# QN908XC register map
Vendor: nxp.com; File version: 1.0
CPU: CM4 r0p1, little endian, no MPU, no FPU, 0x3 interrupt priority bits, 0x0 interrupts
Registers are 32-bit, read-write, reset 0x0 unless marked. A register's access mark holds for its fields unless they carry their own. Offsets are from the block's base; [hi:lo] are bit positions.

## AGC
Base 0x4000C000
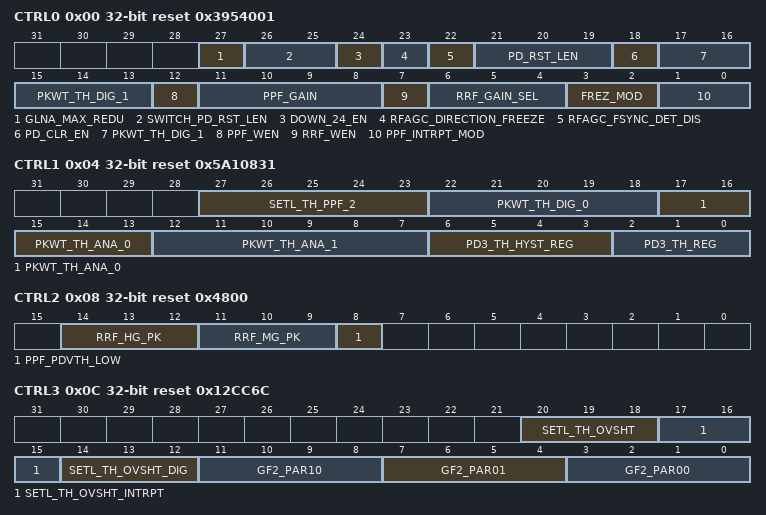
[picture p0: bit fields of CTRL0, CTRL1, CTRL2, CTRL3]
0x00 CTRL0 reset 0x3954001 — AGC control register 0
  [27] GLNA_MAX_REDU — Lna max gain reduce 12dbm0bdisable 1benable
  [26:25] SWITCH_PD_RST_LEN — Pd disable time when direction found rfagc reset00b2us 01b4us 10b8us 11b16us
  [24] DOWN_24_EN — Lna decrease 24dbm0bdisable 1benable
  [23] RFAGC_DIRECTION_FREEZE — Use to disable rfagc gain adjust when switching antenna at direction found mode0b rfagc enable 1brfagc disable
  [22] RFAGC_FSYNC_DET_DIS — Use to control rfagc gain adjust0brfagc stops when sync 1brfagc always on
  [21:19] PD_RST_LEN — Pd disable time when reset0h0us 1h8us 2h16us 7h56us
  [18] PD_CLR_EN — Force clear analog PD
  [17:13] PKWT_TH_DIG_1 — PKWT_TH_DIG + PKWT_TH_DIG_ADD in ccode
  [12] PPF_WEN — Ppf gain write enable
  [11:8] PPF_GAIN — PPF gain controlGain=36-3*PPF_GAIN
  [7] RRF_WEN — Lna gain write enable
  [6:4] RRF_GAIN_SEL — LNA gain controlGAIN=26-12*LNA_GAIN_SEL
  [3:2] FREZ_MOD — Control whether fsm can restore last value when correalation trigh happens
  [1:0] PPF_INTRPT_MOD — Control whether fsm can interrupt
0x04 CTRL1 reset 0x5A10831 — AGC control register 1
  [27:23] SETL_TH_PPF_2 — SETL_TH_PPF_2 + DLY_DIG 1 in ccode
  [22:18] PKWT_TH_DIG_0 — PKWT_TH_DIG in ccode
  [17:13] PKWT_TH_ANA_0 — PKWT_TH_ANA in ccode
  [12:7] PKWT_TH_ANA_1 — PKWT_TH_ANA + PKWT_TH_ANA_ADD
  [6:3] PD3_TH_HYST_REG — Desired upper boundary
  [2:0] PD3_TH_REG — Pd3 threshold
0x08 CTRL2 reset 0x4800 — AGC control register 2
  [14:12] RRF_HG_PK — LNA high gain peak detect threshold selectAMP=(100-8* LNA_HG_PK)mv
  [11:9] RRF_MG_PK — LNA medium gain peak detect threshold selectAMP=(400-25* LNA_MG_PK)mv
  [8] PPF_PDVTH_LOW — PPF peak detect threshold select
0x0C CTRL3 reset 0x12CC6C — AGC control register 3
  [20:18] SETL_TH_OVSHT, [17:15] SETL_TH_OVSHT_INTRPT, [14:12] SETL_TH_OVSHT_DIG, [11:8] GF2_PAR10, [7:4] GF2_PAR01, [3:0] GF2_PAR00
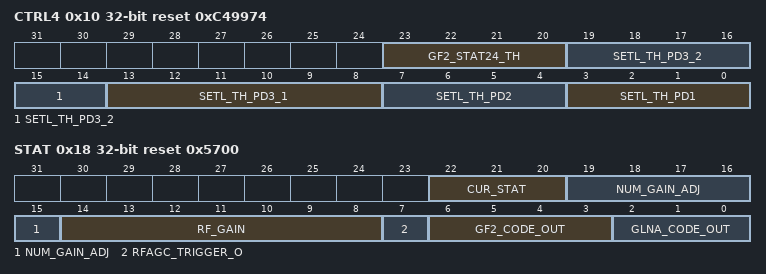
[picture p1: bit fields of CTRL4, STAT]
0x10 CTRL4 reset 0xC49974 — AGC control register 4
  [23:20] GF2_STAT24_TH, [19:14] SETL_TH_PD3_2, [13:8] SETL_TH_PD3_1, [7:4] SETL_TH_PD2, [3:0] SETL_TH_PD1
0x14 CTRL5 — AGC control register 5
  [3:0] TEST_CTRL
0x18 STAT ro reset 0x5700 — AGC status register
  [22:20] CUR_STAT, [19:15] NUM_GAIN_ADJ, [14:8] RF_GAIN, [7] RFAGC_TRIGGER_O, [6:3] GF2_CODE_OUT, [2:0] GLNA_CODE_OUT

## PROP
Base 0x4000D000
0x00 TX_BUF — transmit data buffer input port register
  [7:0] TX_BUF
0x04 RX_BUF ro — received data buffer output register
  [7:0] RX_BUF
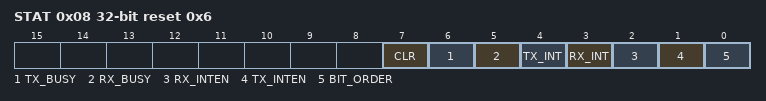
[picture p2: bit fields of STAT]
0x08 STAT reset 0x6 — status register
  [7] CLR — Clear intf control register.
  [6] TX_BUSY ro — TX is busy
  [5] RX_BUSY ro — RX is busy
  [4] TX_INT ro — TX interrupt
  [3] RX_INT ro — RX interrupt
  [2] RX_INTEN — RX interrupt enable
  [1] TX_INTEN — TX interrupt enable
  [0] BIT_ORDER

## FLEXCOMM0 — flexcomm
Base 0x40083000
Same registers: FLEXCOMM1 0x40086000, FLEXCOMM2 0x40087000, FLEXCOMM3 0x4008F000
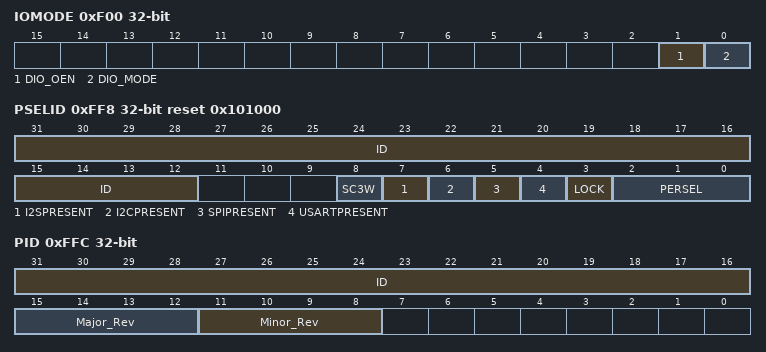
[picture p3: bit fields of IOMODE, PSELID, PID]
0xF00 IOMODE
  [1] DIO_OEN — shared pin direction register
    0=SP_NOEN (shared pin do not output); 1=SP_OEN (shared pin output enable)
  [0] DIO_MODE — IO mode register, SPI share MISO/MOSI at MOSI, USART share TXD/RXD at RXD
    0=NOSHAREPIN (do not share pin); 1=SHAREPIN
0xFF8 PSELID reset 0x101000 — Peripheral Select and Flexcomm ID register.
  [31:12] ID ro — Flexcomm ID.
  [8] SC3W ro — Smart card/SPI 3 wire mode feature indicator. This field is Read-only
    0=NOT_PRESENT (This Flexcomm does not support smart card/SPI 3 wire mdoe feature); 1=PRESENT (This Flexcomm support smart card/SPI 3 wire mode feature)
  [7] I2SPRESENT ro — I 2S present indicator. This field is Read-only.
    0=NOT_PRESENT (This Flexcomm does not include the I2S function.); 1=PRESENT (This Flexcomm includes the I2S function.)
  [6] I2CPRESENT ro — I2C present indicator. This field is Read-only.
    0=NOT_PRESENT (This Flexcomm does not include the I2C function.); 1=PRESENT (This Flexcomm includes the I2C function.)
  [5] SPIPRESENT ro — SPI present indicator. This field is Read-only.
    0=NOT_PRESENT (This Flexcomm does not include the SPI function.); 1=PRESENT (This Flexcomm includes the SPI function.)
  [4] USARTPRESENT ro — USART present indicator. This field is Read-only.
    0=NOT_PRESENT (This Flexcomm does not include the USART function.); 1=PRESENT (This Flexcomm includes the USART function.)
  [3] LOCK — Lock the peripheral select. This field is writable by software.
    0=UNLOCKED (Peripheral select can be changed by software.); 1=LOCKED (Peripheral select is locked and cannot be changed until this Flexcomm or the entire device is reset.)
  [2:0] PERSEL — Peripheral Select. This field is writable by software.
    0=NO_PERIPH_SELECTED (No peripheral selected.); 1=USART (USART function selected.); 2=SPI (SPI function selected.); 3=I2C (I2C function selected.); 4=I2S_TRANSMIT (I2S transmit function selected.); 5=I2S_RECEIVE (I2S receive function selected.)
0xFFC PID ro — Peripheral identification register.
  [31:16] ID — Module identifier for the selected function.
  [15:12] Major_Rev — Major revision of module implementation.
  [11:8] Minor_Rev — Minor revision of module implementation.

## GPIOA — gpio
Base 0x4008C000
Same registers: GPIOB 0x4008D000
0x00 DATA ro — GPIO value register
  [31:0] DATA — data value
0x04 DATAOUT — GPIO output status register
  [31:0] DATAOUT — Data output register value
0x10 OUTENSET — GPIO output enable set register
  [31:0] OUTENSET — output enable clear
0x14 OUTENCLR — GPIO output clear register
  [31:0] OUTENCLR write-1-clears — output enable clear
0x20 INTENSET wo — GPIO interrupt enable set register
  [31:0] INTENSET — interrupt enable set
0x24 INTENCLR — GPIO interrupt enable clear register
  [31:0] INTENCLR write-1-clears — interrupt enable clear
0x28 INTTYPESET wo — GPIO interrupt type set register
  [31:0] INTTYPESET — interrupt type set
0x2C INTTYPECLR — GPIO interrupt type set register
  [31:0] INTTYPECLR write-1-clears — interrupt type clear
0x30 INTPOLSET wo — GPIO interrupt polarity set register
  [31:0] INTPOLSET — interrupt polarity set
0x34 INTPOLCLR — GPIO interrupt polarity clear register
  [31:0] INTPOLCLR write-1-clears — interrupt polarity clear
0x38 INTSTATUS — GPIO interrupt status register
  [31:0] INTSTATUS write-1-clears — interrupt status

## CRC_ENGINE — crc
Base 0x4008E000
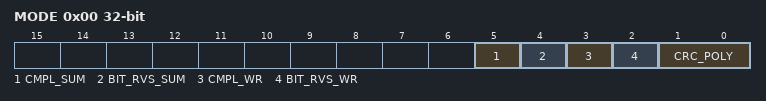
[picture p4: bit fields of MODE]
0x00 MODE — CRC mode register
  [5] CMPL_SUM — CRC sum complement: 1 = 1'-s complement for CRC_SUM 0 = No 1'-s complement for CRC_SUM
  [4] BIT_RVS_SUM — CRC sum bit order: 1 = Bit order reverse for CRC_SUM 0 = No bit order reverse for CRC_SUM
  [3] CMPL_WR — Data complement: 1 = 1'-s complement for CRC_WR_DATA 0 = No 1'-s complement for CRC_WR_DATA
  [2] BIT_RVS_WR — Data bit order: 1 = Bit order reverse for CRC_WR_DATA (per byte) 0 = No bit order reverse for CRC_WR_DATA (per byte)
  [1:0] CRC_POLY — CRC polynomial: 1X = CRC-32 polynomial 01 = CRC-16 polynomial 00 = CRC-CCITT polynomial
0x04 SEED reset 0xFFFF — CRC seed register
  [31:0] CRC_SEED — A write access to this register will load CRC seed value to CRC_SUM register with selected bit order and 1'-s complement pre-processes. A write access to this register will overrule the CRC calculation in progresses.
0x08 SUM ro reset 0xFFFF (SUM_WR_DATA view) — CRC checksum register
  [31:0] CRC_SUM — The most recent CRC sum can be read through this register with selected bit order and 1'-s complement post-processes.
0x08 WR_DATA wo reset not defined (SUM_WR_DATA view) — CRC data register
  [31:0] CRC_WR_DATA — Data written to this register will be taken to perform CRC calculation with selected bit order and 1'-s complement pre-process. Any write size 8, 16 or 32-bit are allowed and accept back-to-back transactions.
